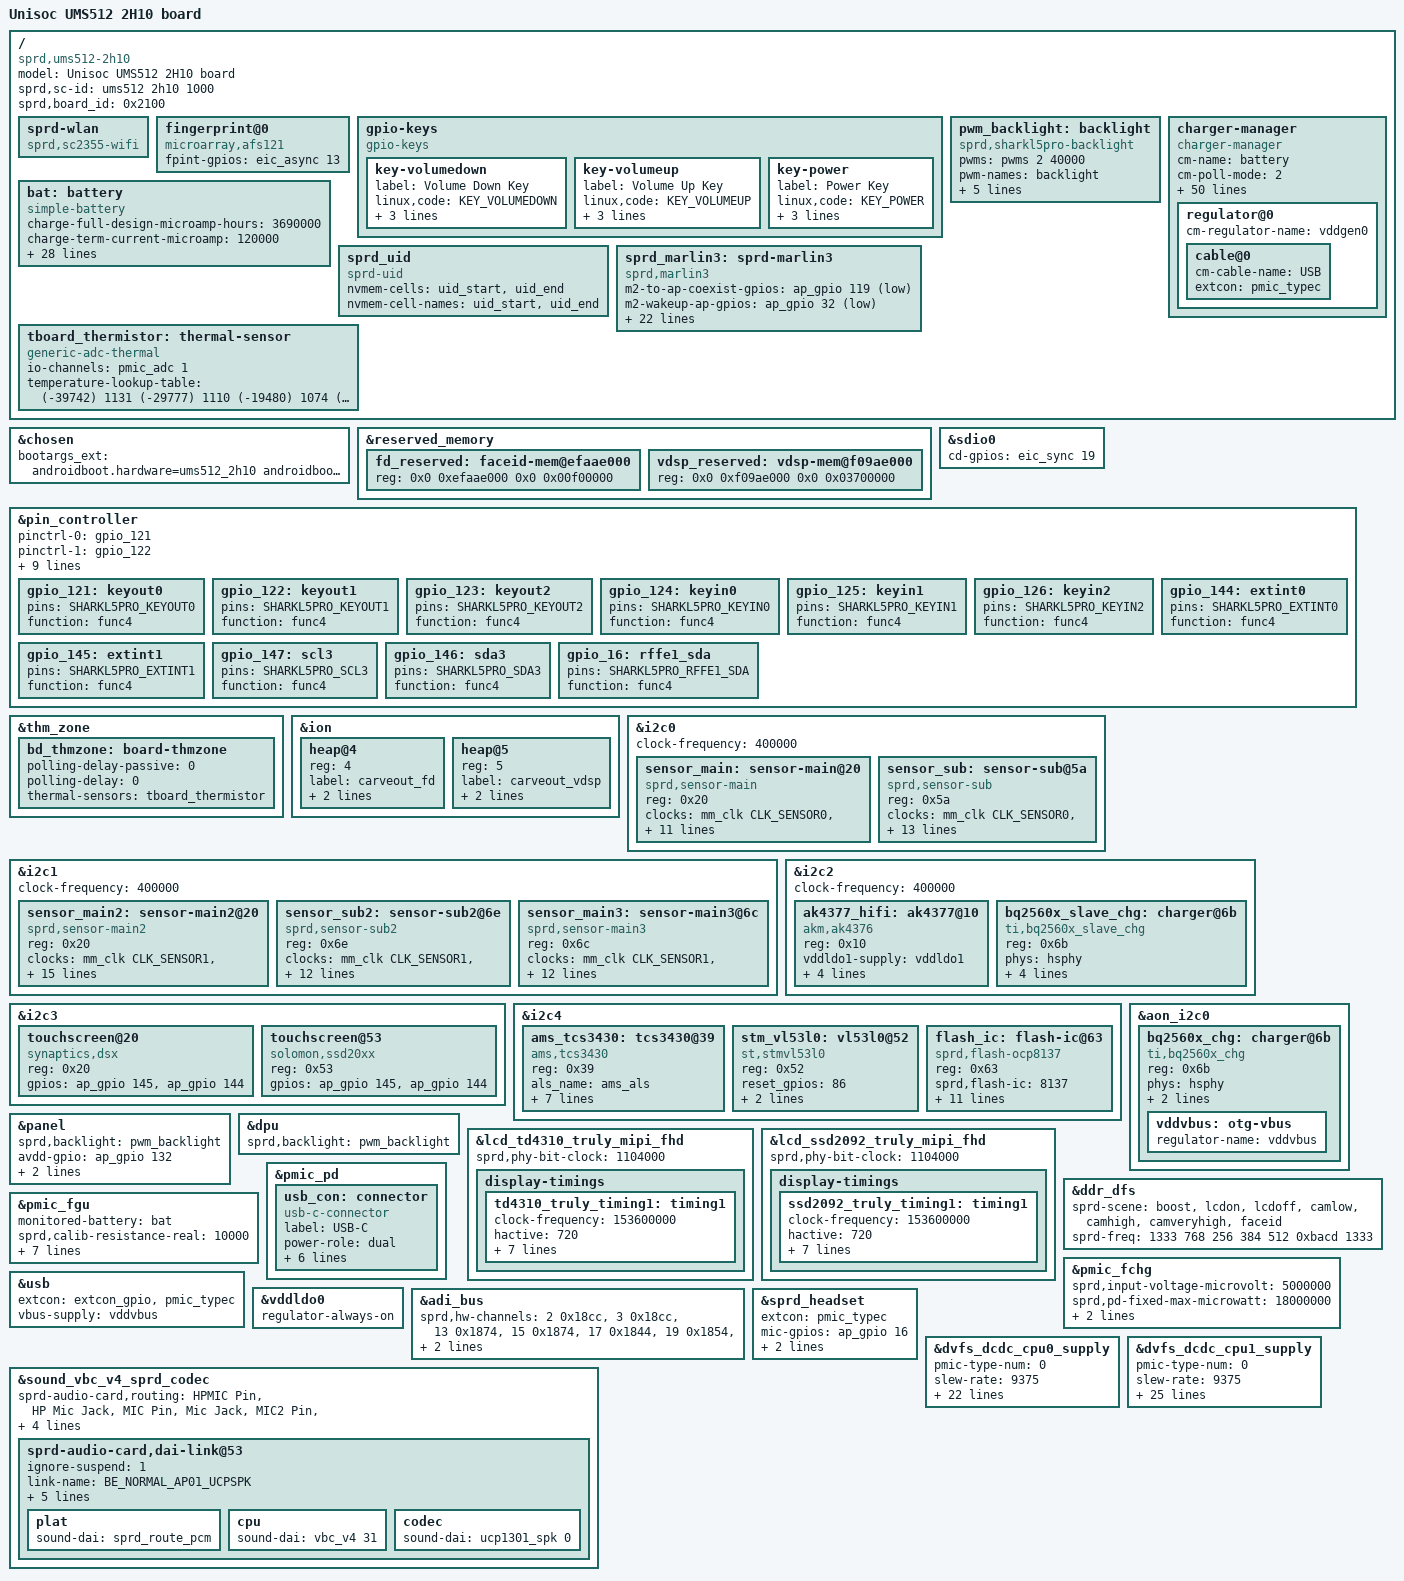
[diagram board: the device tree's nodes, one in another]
/dts-v1/;
/plugin/;

#include <dt-bindings/input/input.h>
#include <dt-bindings/gpio/gpio.h>
#include <dt-bindings/usb/pd.h>
#include <dt-bindings/interrupt-controller/arm-gic.h>
#include <dt-bindings/clock/sprd,sharkl5pro-clk.h>
#include <dt-bindings/mfd/sprd,sc2730-regs.h>
#include <dt-bindings/mfd/sprd,sc2730-mask.h>
#include "lcd/lcd_td4310_truly_mipi_fhd.dtsi"
#include "lcd/lcd_ssd2092_truly_mipi_fhd.dtsi"
#include "lcd/lcd_dummy_mipi.dtsi"

/ {

	model = "Unisoc UMS512 2H10 board";
	compatible = "sprd,ums512-2h10";
	sprd,sc-id = "ums512 2h10 1000";
	sprd,board_id = <0x2100>; //XX00:base board,XX00~XXFF:customize board

	fragment {
		target-path = "/";
		__overlay__ {
			sprd-wlan {
				compatible = "sprd,sc2355-wifi";
			};

			fingerprint@0 {
				compatible = "microarray,afs121";
				fpint-gpios = <&eic_async 13 0>;
			};

			gpio-keys {
				compatible = "gpio-keys";

				key-volumedown {
					label = "Volume Down Key";
					linux,code = <KEY_VOLUMEDOWN>;
					gpios = <&ap_gpio 124 GPIO_ACTIVE_LOW>;
					debounce-interval = <2>;
					wakeup-source;
				};

				key-volumeup {
					label = "Volume Up Key";
					linux,code = <KEY_VOLUMEUP>;
					gpios = <&pmic_eic 4 GPIO_ACTIVE_HIGH>;
					debounce-interval = <2>;
					wakeup-source;
				};

				key-power {
					label = "Power Key";
					linux,code = <KEY_POWER>;
					gpios = <&pmic_eic 1 GPIO_ACTIVE_LOW>;
					debounce-interval = <2>;
					wakeup-source;
				};
			};

			pwm_backlight: backlight {
				compatible = "sprd,sharkl5pro-backlight";
				pwms = <&pwms 2 40000>;
				pwm-names = "backlight";
				sprd,max-brightness-level = <880>;
				default-brightness-level = <250>;
				sprd,brightness-scale = <1023>;
				brightness-levels = <
							  0   3   4   5   6   7
					  8   9  10  11  12  13  14  15  16  17
					 18  19  20  21  22  23  24  25  26  27
					 28  29  31  33  35  37  39  41  43  45
					 46  48  50  52  54  56  58  60  62  64
					 66  68  70  72  74  76  78  80  82  84
					 86  88  90  92  94  96  98 100 102 104
					106 108 110 112 114 116 118 120 122 124
					126 128 130 132 134 136 138 140 142 144
					146 148 150 152 154 156 158 160 162 164
					166 169 172 175 178 181 184 187 190 193
					196 199 202 205 208 211 214 217 220 223
					226 229 232 235 238 241 244 247 250 253
					256 259 262 265 268 271 274 277 280 283
					286 290 294 298 302 306 310 314 318 322
					326 330 334 338 342 346 350 354 358 362
					366 370 374 378 382 386 390 394 398 402
					406 410 414 418 422 426 430 434 438 442
					446 451 456 461 466 471 476 481 486 491
					496 501 506 511 516 521 526 531 536 541
					546 551 556 561 566 571 576 581 586 591
					596 601 606 611 616 621 626 631 636 641
					646 652 658 664 670 676 682 688 694 700
					706 712 718 724 730 736 742 748 754 760
					766 772 778 784 790 796 802 808 814 820
					826 832 838 844 850 856 862 868 874 880
				>;
			};

			bat: battery {
				compatible = "simple-battery";
				charge-full-design-microamp-hours = <3690000>;
				charge-term-current-microamp = <120000>;
				constant_charge_voltage_max_microvolt = <4400000>;
				factory-internal-resistance-micro-ohms = <130000>;
				voltage-min-design-microvolt = <3450000>;
				fast-charge-threshold-microvolt = <4100000>;
				ocv-capacity-celsius = <20>;
				ocv-capacity-table-0 = <4380000 100>, <4317000 95>, <4258000 90>,
							<4200000 85>, <4145000 80>, <4092000 75>,
							<4047000 70>, <3990000 65>, <3955000 60>,
							<3900000 55>, <3861000 50>, <3834000 45>,
							<3813000 40>, <3796000 35>, <3783000 30>,
							<3770000 25>, <3752000 20>, <3730000 15>,
							<3698000 10>, <3687000 5>, <3400000 0>;
				voltage-temp-table = <1095000 800>, <986000 850>, <878000 900>,
							  <775000 950>, <678000 1000>, <590000 1050>,
							  <510000 1100>, <440000 1150>, <378000 1200>,
							  <324000 1250>, <278000 1300>, <238000 1350>,
							  <204000 1400>, <175000 1450>, <150000 1500>,
							  <129000 1550>, <111000 1600>, <96000 1650>;
				capacity-temp-table = <45 100>, <25 100>, <10 98>, <0 93>, <(-10) 85>, <(-20) 64>;
				resistance-temp-table = <45 77>, <25 100>, <10 546>, <0 769>, <(-10) 892>, <(-20) 923>;
				charge-sdp-current-microamp = <500000 500000>;
				charge-dcp-current-microamp = <2000000 3000000>;
				charge-cdp-current-microamp = <1500000 1500000>;
				charge-unknown-current-microamp = <500000 500000>;
				charge-fchg-current-microamp = <3000000 2000000>;
			};

			charger-manager {
				compatible = "charger-manager";
				cm-name = "battery";
				cm-poll-mode = <2>;
				cm-poll-interval = <15000>;
				cm-battery-stat = <2>;

				cm-fullbatt-vchkdrop-ms = <30000>;
				cm-fullbatt-vchkdrop-volt = <60000>;
				cm-fullbatt-voltage = <4350000>;
				cm-fullbatt-current = <120000>;
				cm-fullbatt-capacity = <100>;

				cm-chargers = "bq2560x_charger", "bq2560x_slave_charger";
				cm-fast-chargers = "sc2730_fast_charger";
				cm-fuel-gauge = "sc27xx-fgu";

				/* in deci centigrade */
				cm-battery-cold = <200>;
				cm-battery-cold-in-minus;
				cm-battery-hot = <800>;
				cm-battery-temp-diff = <100>;

				/* Allow charging for 6hr */
				cm-charging-max = <21600000>;
				/* recovery charging after stop charging 45min */
				cm-discharging-max = <2700000>;

				/* the interval to feed charger watchdog */
				cm-wdt-interval = <60>;

				/* drop voltage in microVolts to allow shutdown */
				cm-shutdown-voltage = <3100000>;

				/* when 99% of the time is exceeded, it will be forced to 100% */
				cm-tickle-time-out = <1500>;

				/* how much time to allow capacity change */
				cm-one-cap-time = <30>;

				/* when the safe charging voltage is exceeded, stop charging */
				cm-charge-voltage-max = <6500000>;
				/* drop voltage in microVolts to restart charging */
				cm-charge-voltage-drop = <700000>;

				/* when the safe charging voltage is exceeded, stop charging */
				cm-fast-charge-voltage-max = <10500000>;
				/* drop voltage in microVolts to restart charging */
				cm-fast-charge-voltage-drop = <700000>;

				cm-thermal-zone = "board-thmzone";

				cm-dcp-jeita-temp-table = <1000 1030 0 4400000>, <1150 1180 700000 4400000>,
					<1450 1420 2000000 4400000>, <1600 1570 700000 4100000>;
				cm-sdp-jeita-temp-table = <1000 1030 0 4400000>, <1150 1180 500000 4400000>,
					<1450 1420 500000 4400000>, <1600 1570 500000 4100000>;
				cm-cdp-jeita-temp-table = <1000 1030 0 4400000>, <1150 1180 700000 4400000>,
					<1450 1420 1500000 4400000>, <1600 1570 700000 4100000>;
				cm-unknown-jeita-temp-table = <1000 1030 0 4400000>, <1150 1180 500000 4400000>,
					<1450 1420 500000 4400000>, <1600 1570 500000 4100000>;
				cm-fchg-jeita-temp-table = <1000 1030 0 4400000>, <1150 1180 800000 4400000>,
					<1450 1420 3000000 4400000>, <1600 1570 800000 4100000>;

				monitored-battery = <&bat>;

				cm-cap-remap-table = <1 2 3>, <2 3 2>, <98 99 2>, <99 100 3>;

				regulator@0 {
					cm-regulator-name = "vddgen0";
					cable@0 {
						cm-cable-name = "USB";
						extcon = <&pmic_typec>;
					};
				};
			};

			sprd_uid {
				compatible = "sprd-uid";
				nvmem-cells = <&uid_start>, <&uid_end>;
				nvmem-cell-names = "uid_start", "uid_end";
			};

			sprd_marlin3: sprd-marlin3 {
				compatible = "sprd,marlin3";
				m2-to-ap-coexist-gpios = <&ap_gpio 119 GPIO_ACTIVE_LOW>;
				m2-wakeup-ap-gpios = <&ap_gpio 32 GPIO_ACTIVE_LOW>;
				permit-ap-send-gpios = <&ap_gpio 121 GPIO_ACTIVE_LOW>;
				reset-gpios = <&ap_gpio 97 GPIO_ACTIVE_LOW>;
				enable-gpios = <&ap_gpio 143 GPIO_ACTIVE_LOW>;
				m2-to-ap-irq-gpios = <&ap_gpio 96 GPIO_ACTIVE_LOW>;
				avdd12-supply = <&vddwcn>;
				avdd33-supply = <&vddwifipa>;
				dcxo18-supply = <&vddsim2>;

				clock-names = "clk_32k","source","enable";
				clocks = <&aon_clk CLK_AUX0>,
					 <&ext_32k>,
					 <&aonapb_gate CLK_AUX0_EB>;

				sdhci-name = <&sdio1>;
				sprd,btwf-file-name = "/dev/block/platform/soc/soc:ap-apb/71400000.sdio/by-name/wcnmodem";
				sprd,gnss-file-name = "/dev/block/platform/soc/soc:ap-apb/71400000.sdio/by-name/gnssmodem";
				adma-tx;
				adma-rx;
				/*
				 * bound parameter:
				 * [0]:addr offset, [1]:mask, [2]:unboundval, [3]:boundval
				 */
				avdd12-parent-bound-chip = <REG_ANA_SLP_DCDC_PD_CTRL MASK_ANA_SLP_DCDCGEN1_PD_EN 0x0 MASK_ANA_SLP_DCDCGEN1_PD_EN>;
				avdd12-bound-wbreq = <REG_ANA_LDO_XTL_EN10 MASK_ANA_LDO_VDDWCN_EXT_XTL3_EN 0x0 MASK_ANA_LDO_VDDWCN_EXT_XTL3_EN>;
				avdd33-bound-wbreq = <REG_ANA_LDO_XTL_EN11 MASK_ANA_LDO_VDDWIFIPA_EXT_XTL3_EN 0x0 MASK_ANA_LDO_VDDWIFIPA_EXT_XTL3_EN>;
			};

			tboard_thermistor:thermal-sensor {
				compatible = "generic-adc-thermal";
				#thermal-sensor-cells = <0>;
				io-channels = <&pmic_adc 1>;
				io-channel-names = "sensor-channel";
				temperature-lookup-table = <    (-39742) 1131
								(-29777) 1110
								(-19480) 1074
								(-4679) 983
								10110 838
								24805 654
								44922 413
								54903 316
								64895 238
								74884 178
								84883 133
								94883 100
								104880 75
								114889 57
								124872 43 >;
			};
		};
	};
};

&chosen {
	bootargs_ext = "androidboot.hardware=ums512_2h10 androidboot.dtbo_idx=0";
};

&reserved_memory {

	fd_reserved: faceid-mem@efaae000 {
		reg = <0x0 0xefaae000 0x0 0x00f00000>;
	};

	vdsp_reserved: vdsp-mem@f09ae000 {
		reg = <0x0 0xf09ae000 0x0 0x03700000>;
	};
/*
	gpu_reserved: gpu-mem@fb8ae000 {
		reg = <0x0 0xfb8ae000 0x0 0x01e5a000>;
	};
*/
};

&sdio0 {
	cd-gpios = <&eic_sync 19 GPIO_ACTIVE_HIGH>;
};

&pin_controller {
	pinctrl-names =
	/* keyout0 ~ keyout2 */
	"gpio_121", "gpio_122", "gpio_123",
	/* keyin0 ~ keyin2 */
	"gpio_124", "gpio_125", "gpio_126",
	/* extint0, extint1, scl3, sda3, sda */
	"gpio_144", "gpio_145", "gpio_146", "gpio_147", "gpio_16";

	pinctrl-0 = <&gpio_121>;
	pinctrl-1 = <&gpio_122>;
	pinctrl-2 = <&gpio_123>;
	pinctrl-3 = <&gpio_124>;
	pinctrl-4 = <&gpio_125>;
	pinctrl-5 = <&gpio_126>;
	pinctrl-6 = <&gpio_144>;
	pinctrl-7 = <&gpio_145>;
	pinctrl-8 = <&gpio_146>;
	pinctrl-9 = <&gpio_147>;
	pinctrl-10 = <&gpio_16>;

	gpio_121: keyout0 {
		pins = "SHARKL5PRO_KEYOUT0";
		function = "func4";
	};

	gpio_122: keyout1 {
		pins = "SHARKL5PRO_KEYOUT1";
		function = "func4";
	};

	gpio_123: keyout2 {
		pins = "SHARKL5PRO_KEYOUT2";
		function = "func4";
	};

	gpio_124: keyin0 {
		pins = "SHARKL5PRO_KEYIN0";
		function = "func4";
	};

	gpio_125: keyin1 {
		pins = "SHARKL5PRO_KEYIN1";
		function = "func4";
	};

	gpio_126: keyin2 {
		pins = "SHARKL5PRO_KEYIN2";
		function = "func4";
	};

	gpio_144: extint0 {
		pins = "SHARKL5PRO_EXTINT0";
		function = "func4";
	};

	gpio_145: extint1 {
		pins = "SHARKL5PRO_EXTINT1";
		function = "func4";
	};

	gpio_147: scl3 {
		pins = "SHARKL5PRO_SCL3";
		function = "func4";
	};

	gpio_146: sda3 {
		pins = "SHARKL5PRO_SDA3";
		function = "func4";
	};

	gpio_16: rffe1_sda {
		pins = "SHARKL5PRO_RFFE1_SDA";
		function = "func4";
	};
};

&thm_zone {
	bd_thmzone: board-thmzone {
		polling-delay-passive = <0>;
		polling-delay = <0>;
		thermal-sensors = <&tboard_thermistor>;
	};
};

&ion {
	heap@4 {
		reg = <4>;
		label = "carveout_fd";
		type = <2>;
		memory-region = <&fd_reserved>;
	};

	heap@5 {
		reg = <5>;
		label = "carveout_vdsp";
		type = <2>;
		memory-region = <&vdsp_reserved>;
	};
};

&i2c0 {
	status = "okay";
	clock-frequency = <400000>;

	sensor_main: sensor-main@20 {
		compatible = "sprd,sensor-main";
		reg = <0x20>;
		clock-names = "clk_src","sensor_eb",
			"clk_96m","clk_76m8",
			"clk_48m","clk_26m";
		clocks = <&mm_clk CLK_SENSOR0>,<&mm_gate CLK_MM_SENSOR0_EB>,
				<&pll2 CLK_TWPLL_96M>,<&pll2 CLK_TWPLL_76M8>,
				<&pll2 CLK_TWPLL_48M>,<&ext_26m>;
		vddio-supply = <&vddcamio>;
		vddcama-supply = <&vddcama0>;
		vddcamd-supply = <&vddcamd0>;
		vddcammot-supply = <&vddcammot>;
		reset-gpios = <&ap_gpio 44 0>;
		power-down-gpios = <&ap_gpio 46 0>;
		sprd,phyid = <0>;
		csi = <&csi0>;
	};

	sensor_sub: sensor-sub@5a {
		compatible = "sprd,sensor-sub";
		reg = <0x5a>;
		clock-names = "clk_src","sensor_eb",
			"clk_96m","clk_76m8",
			"clk_48m","clk_26m";
		clocks = <&mm_clk CLK_SENSOR0>,<&mm_gate CLK_MM_SENSOR0_EB>,
				<&pll2 CLK_TWPLL_96M>,<&pll2 CLK_TWPLL_76M8>,
				<&pll2 CLK_TWPLL_48M>,<&ext_26m>;
		vddio-supply = <&vddcamio>;
		vddcama-supply = <&vddcama0>;
		vddcamd-supply = <&vddcamd0>;
		vddcammot-supply = <&vddcammot>;
		reset-gpios = <&ap_gpio 41 0>;
		power-down-gpios = <&ap_gpio 40 0>;
		mipi-switch-en-gpios = <&ap_gpio 55 0>;
		mipi-switch-mode-gpios = <&ap_gpio 8 0>;
		sprd,phyid = <1>;
		csi = <&csi0>;
	};
};

&i2c1 {
	status = "okay";
	clock-frequency = <400000>;

	sensor_main2: sensor-main2@20 {
		compatible = "sprd,sensor-main2";
		reg = <0x20>;
		clock-names = "clk_src","sensor_eb",
			"clk_96m","clk_76m8",
			"clk_48m","clk_26m";
		clocks = <&mm_clk CLK_SENSOR1>,<&mm_gate CLK_MM_SENSOR1_EB>,
				<&pll2 CLK_TWPLL_96M>,<&pll2 CLK_TWPLL_76M8>,
				<&pll2 CLK_TWPLL_48M>,<&ext_26m>;
		vddio-supply = <&vddcamio>;
		vddcama-supply = <&vddcama1>;
		vddcamd-supply = <&vddcamd1>;
		vddcammot-supply = <&vddcammot>;
		avdd-gpios = <&ap_gpio 33 0>;
		mot-gpios = <&ap_gpio 88 0>;
		reset-gpios = <&ap_gpio 45 0>;
		power-down-gpios = <&ap_gpio 47 0>;
		mipi-switch-en-gpios = <&ap_gpio 55 0>;
		mipi-switch-mode-gpios = <&ap_gpio 8 0>;
		sprd,phyid = <1>;
		csi = <&csi1>;
	};

	sensor_sub2: sensor-sub2@6e {
		compatible = "sprd,sensor-sub2";
		reg = <0x6e>;
		clock-names = "clk_src","sensor_eb",
			"clk_96m","clk_76m8",
			"clk_48m","clk_26m";
		clocks = <&mm_clk CLK_SENSOR1>,<&mm_gate CLK_MM_SENSOR1_EB>,
			<&pll2 CLK_TWPLL_96M>,<&pll2 CLK_TWPLL_76M8>,
			<&pll2 CLK_TWPLL_48M>,<&ext_26m>;
		vddio-supply = <&vddcamio>;
		vddcama-supply = <&vddcama1>;
		vddcamd-supply = <&vddcamd1>;
		vddcammot-supply = <&vddcammot>;
		mot-gpios = <&ap_gpio 88 0>;
		reset-gpios = <&ap_gpio 41 0>;
		power-down-gpios = <&ap_gpio 40 0>;
		sprd,phyid = <2>;
		csi = <&csi2>;
	};

	sensor_main3: sensor-main3@6c {
		compatible = "sprd,sensor-main3";
		reg = <0x6c>;
		clock-names = "clk_src","sensor_eb",
			"clk_96m","clk_76m8",
			"clk_48m","clk_26m";
		clocks = <&mm_clk CLK_SENSOR1>,<&mm_gate CLK_MM_SENSOR1_EB>,
				<&pll2 CLK_TWPLL_96M>,<&pll2 CLK_TWPLL_76M8>,
				<&pll2 CLK_TWPLL_48M>,<&ext_26m>;
		vddio-supply = <&vddcamio>;
		vddcama-supply = <&vddcama1>;
		vddcamd-supply = <&vddcamd1>;
		vddcammot-supply = <&vddcammot>;
		mot-gpios = <&ap_gpio 88 0>;
		reset-gpios = <&ap_gpio 41 0>;
		power-down-gpios = <&ap_gpio 40 0>;
		sprd,phyid = <2>;
		csi = <&csi2>;
	};
};

&i2c2 {
	status = "okay";
	clock-frequency = <400000>;

	ak4377_hifi: ak4377@10 {
		compatible = "akm,ak4376";
		reg = <0x10>;
		#sound-dai-cells = <1>;
		vddldo1-supply = <&vddldo1>;
		sprd,vddldo1-voltage = <1800000>;
		ak4377,pdn-gpio = <&ap_gpio 116 GPIO_ACTIVE_HIGH>;

		clock-names = "clk_48M", "source", "enable";
		clocks = <&aon_clk CLK_AUX1>,
			 <&pll2 CLK_TWPLL_19M2>,
			 <&aonapb_gate CLK_AUX1_EB>;
	};

	bq2560x_slave_chg: charger@6b {
		compatible = "ti,bq2560x_slave_chg";
		reg = <0x6b>;
		phys = <&hsphy>;
		monitored-battery = <&bat>;
		extcon = <&extcon_gpio>;
		enable-gpio = <&ap_gpio 135 GPIO_ACTIVE_HIGH>;
		role-slave;
	};
};

&i2c3 {
	status = "okay";

	touchscreen@20 {
		compatible = "synaptics,dsx";
		reg = <0x20>;
		gpios = <&ap_gpio 145 GPIO_ACTIVE_HIGH
			&ap_gpio 144 GPIO_ACTIVE_HIGH>;
	};

	touchscreen@53 {
		compatible = "solomon,ssd20xx";
		reg = <0x53>;
		gpios = <&ap_gpio 145 GPIO_ACTIVE_HIGH
			&ap_gpio 144 GPIO_ACTIVE_HIGH>;
	};
};

&i2c4 {
	status = "okay";

	ams_tcs3430: tcs3430@39 {
		compatible = "ams,tcs3430";
		reg = <0x39>;
		als_name = "ams_als";
		persist = <0>;
		als_time_ms = <100>;
		als_gain = <64>;
		int_config = <0>;
		als_can_wake = <1>;
		irq_gpios = <112>;
		interrupt-parent = <&ap_gpio>;
		//interrupts = <112 IRQ_TYPE_LEVEL_LOW>;
	};

	stm_vl53l0: vl53l0@52 {
		compatible = "st,stmvl53l0";
		reg = <0x52>;
		reset_gpios = <86>;
		irq_gpios = <87>;
		interrupt-parent = <&ap_gpio>;
		//interrupts = <87 IRQ_TYPE_LEVEL_LOW>;
	};

	flash_ic: flash-ic@63 {
		compatible = "sprd,flash-ocp8137";
		reg = <0x63>;
		sprd,flash-ic = <8137>;
		sprd,torch = <1>;
		sprd,preflash = <1>;
		sprd,highlight = <1>;
		sprd,torch-level = <128>;
		sprd,preflash-level = <128>;
		sprd,highlight-level = <128>;
		sprd,lvfm-enable = <1>;
		flash-chip-en-gpios = <&ap_gpio 136 0>;
		flash-torch-en-gpios = <&ap_gpio 139 0>;
		flash-en-gpios = <&ap_gpio 137 0>;
		flash-sync-gpios = <&ap_gpio 138 0>;
	};

};

&aon_i2c0 {
	status = "okay";

	bq2560x_chg: charger@6b {
		compatible = "ti,bq2560x_chg";
		reg = <0x6b>;
		phys = <&hsphy>;
		monitored-battery = <&bat>;
		extcon = <&extcon_gpio>;
		vddvbus:otg-vbus {
			regulator-name = "vddvbus";
		};
	};
};

&panel {
	sprd,backlight = <&pwm_backlight>;
	avdd-gpio = <&ap_gpio 132 GPIO_ACTIVE_HIGH>;
	avee-gpio = <&ap_gpio 133 GPIO_ACTIVE_HIGH>;
	reset-gpio = <&ap_gpio 50 GPIO_ACTIVE_HIGH>;
};

&dpu {
	sprd,backlight = <&pwm_backlight>;
};

&lcd_td4310_truly_mipi_fhd {
	sprd,phy-bit-clock = <1104000>;  /* kbps */

	display-timings {
		td4310_truly_timing1: timing1 {
			clock-frequency = <153600000>;
			hactive = <720>;
			vactive = <1440>;
			hback-porch = <20>;
			hfront-porch = <50>;
			vback-porch = <28>;
			vfront-porch = <4>;
			hsync-len = <2>;
			vsync-len = <2>;
		};
	};
};

&lcd_ssd2092_truly_mipi_fhd {
	sprd,phy-bit-clock = <1104000>;  /* kbps */

	display-timings {
		ssd2092_truly_timing1: timing1 {
			clock-frequency = <153600000>;
			hactive = <720>;
			vactive = <1440>;
			hback-porch = <20>;
			hfront-porch = <20>;
			vback-porch = <43>;
			vfront-porch = <76>;
			hsync-len = <4>;
			vsync-len = <1>;
		};
	};
};

&ddr_dfs {
	sprd-scene = "boost", "lcdon", "lcdoff", "camlow",
		"camhigh", "camveryhigh", "faceid";
	sprd-freq = <1333 768 256 384 512 0xbacd 1333>;
};

&pmic_fgu {
	monitored-battery = <&bat>;
	sprd,calib-resistance-real = <10000>;
	sprd,calib-resistance-spec = <20000>;
	first-calib-voltage = <3630000>;
	first-calib-capacity = <50>;
	fgu-capacity-track;
	fullbatt-track-end-vol = <4345>;
	fullbatt-track-end-cur = <130>;
	phys = <&hsphy>;
};

&pmic_fchg {
	sprd,input-voltage-microvolt = <5000000>;
	sprd,pd-fixed-max-microwatt = <18000000>;
	sprd,support-sfcp;
	phys = <&hsphy>;
};

&pmic_pd {
	status = "okay";
	usb_con: connector {
		compatible = "usb-c-connector";
		label = "USB-C";
		power-role = "dual";
		try-power-role = "sink";
		source-pdos = <PDO_FIXED(5000, 400, PDO_FIXED_USB_COMM)>;
		sink-pdos = <PDO_FIXED(5000, 3000, PDO_FIXED_USB_COMM)>;
		op-sink-microwatt = <10000000>;
	};
};

&usb {
	extcon = <&extcon_gpio>, <&pmic_typec>;
	vbus-supply = <&vddvbus>;
};

&vddldo0 {
	regulator-always-on;
};

&adi_bus {
	sprd,hw-channels = <2 0x18cc>, <3 0x18cc>, <13 0x1874>, <15 0x1874>,
			 <17 0x1844>,<19 0x1854>, <21 0x1864>, <30 0x1820>,
			 <35 0x19b8>, <39 0x19ac>, <32 0x197c>, <33 0x1988>;
};

&sprd_headset {
	status = "okay";
	extcon = <&pmic_typec>;
	mic-gpios = <&ap_gpio 16 GPIO_ACTIVE_HIGH>;
	lr-gpios = <&ap_gpio 15 GPIO_ACTIVE_HIGH>;
	sprd,3pole-adc-threshold = <112>;
};

&sound_vbc_v4_sprd_codec {
	status = "okay";
	sprd-audio-card,routing =
		"HPMIC Pin", "HP Mic Jack",
		"MIC Pin", "Mic Jack",
		"MIC2 Pin", "Aux Mic Jack",
		"HeadPhone Jack", "HP Pin",
		"Ext Spk", "SPK Pin",
		"UCP1301 SPK ON", "SPK Pin",
		"Ext Spk", "UCP1301 SPK",
		"DMIC Pin", "DMic Jack",
		"DMIC1 Pin", "DMic1 Jack",
		"Ext Ear", "EAR Pin";

	/* 35: ucp1301 normal ap01 */
	sprd-audio-card,dai-link@53 {
		ignore-suspend = <1>;
		link-name = "BE_NORMAL_AP01_UCPSPK";
		stream-name = "BE_ST_NORMAL_AP01_UCPSPK";
		no-pcm = <1>;
		dpcm-playback = <1>;
		be-id = <0>;
		dai-format = "i2s";
		plat {
			sound-dai = <&sprd_route_pcm>;
		};
		cpu {
			sound-dai = <&vbc_v4 31>;
		};
		codec {
			sound-dai = <&ucp1301_spk 0>;
		};
	};

	/*
	 * node 54 and node 55 (index 36 and 37) are reserved for
	 * "ucp1301-spk2" and "ucp1301-rcv"
	 * nodes from 56 to 67 (index from 38 to 49) are used by HIFI
	 */
};

&dvfs_dcdc_cpu0_supply {
	pmic-type-num = <0>;
	slew-rate = <9375>; /* 9375uV/us */
	top-dvfs-adi-state = <0x70 0 0xf>;
	voltage-grade-num = <7>;
	voltage-grade = <0 0xf0 0xf4 0 0x1ff>,
		<1 0xf0 0xf4 9 0x1ff>,
		<2 0x100 0xf4 18 0x1ff>,
		<3 0x110 0xf8 0 0x1ff>,
		<4 0x120 0xf8 9 0x1ff>,
		<5 0x130 0xf8 18 0x1ff>,
		<6 0x140 0xfc 0 0x1ff>;
	voltage-up-delay = <50 0x58 0 0xffff 0x600>,
		<100 0x58 16 0xffff 0xa00>,
		<150 0x54 0 0xffff 0xf00>,
		<200 0x54 16 0xffff 0x1400>,
		<250 0x50 0 0xffff 0x1900>,
		<300 0x50 16 0xffff 0x1e00>,
		<350 0x110 0 0xffff 0x2300>;
	voltage-down-delay = <50 0x64 0 0xffff 0x600>,
		<100 0x64 16 0xffff 0xa00>,
		<150 0x60 0 0xffff 0xf00>,
		<200 0x60 16 0xffff 0x1400>,
		<250 0x5c 0 0xffff 0x1900>,
		<300 0x5c 16 0xffff 0x1e00>,
		<350 0x114 0 0xffff 0x2300>;
	tuning-latency-us = <0>;
	chnl-in-i2c = <0>;
};

&dvfs_dcdc_cpu1_supply {
	pmic-type-num = <0>;
	slew-rate = <9375>; /* 9375uV/us */
	supply-type-sel = <0x120 0 0>;
	top-dvfs-adi-state = <0x9c 0 0xf>;
	voltage-grade-num = <6>;
	voltage-grade = <0 0xf0 0x100 0 0x1ff>,
		<1 0x100 0x100 9 0x1ff>,
		<2 0x110 0x100 18 0x1ff>,
		<3 0x120 0x104 0 0x1ff>,
		<4 0x130 0x104 9 0x1ff>,
		<5 0x140 0x104 18 0x1ff>;
	voltage-up-delay = <50 0x84 0 0xffff 0x1600>,
		<100 0x84 16 0xffff 0xa00>,
		<150 0x80 0 0xffff 0x1f00>,
		<200 0x80 16 0xffff 0x1400>,
		<250 0x7c 0 0xffff 0x1900>,
		<300 0x7c 16 0xffff 0x1e00>,
		<350 0x118 0 0xffff 0x2300>;
	voltage-down-delay = <50 0x90 0 0xffff 0x600>,
		<100 0x90 16 0xffff 0xa00>,
		<150 0x8c 0 0xffff 0xf00>,
		<200 0x8c 16 0xffff 0x1400>,
		<250 0x88 0 0xffff 0x1900>,
		<300 0x88 16 0xffff 0x1e00>,
		<350 0x11c 0 0xffff 0x2300>;
	tuning-latency-us = <200>;
	chnl-in-i2c = <0>;
};
